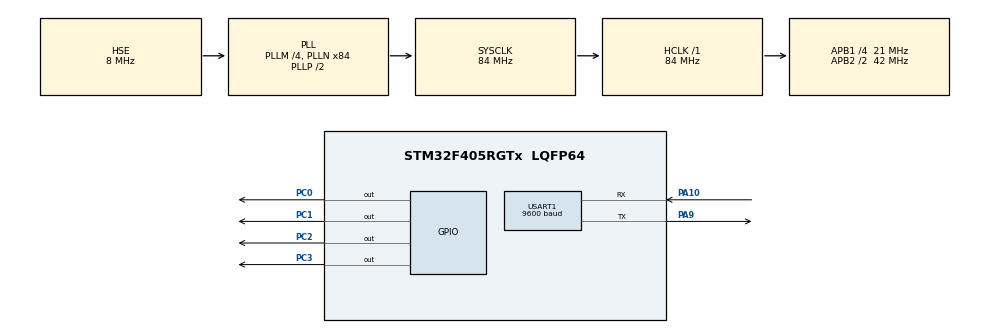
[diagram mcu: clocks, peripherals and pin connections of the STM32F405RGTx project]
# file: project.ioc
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Mcu.Family=STM32F4
Mcu.Name=STM32F405RGTx
Mcu.Package=LQFP64
NVIC.PriorityGroup=NVIC_PRIORITYGROUP_4
PA10.Mode=Asynchronous
PA10.Signal=USART1_RX
PA9.Mode=Asynchronous
PA9.Signal=USART1_TX
PC0.GPIO_ModeDefaultOutputPP=GPIO_MODE_OUTPUT_PP
PC0.GPIO_PuPd=GPIO_PULLUP
PC0.GPIO_Speed=GPIO_SPEED_FREQ_HIGH
PC0.PinState=GPIO_PIN_RESET
PC0.Signal=GPIO_Output
PC1.GPIO_PuPd=GPIO_PULLUP
PC1.GPIO_Speed=GPIO_SPEED_FREQ_HIGH
PC1.PinState=GPIO_PIN_RESET
PC1.Signal=GPIO_Output
PC2.GPIO_PuPd=GPIO_PULLUP
PC2.GPIO_Speed=GPIO_SPEED_FREQ_HIGH
PC2.Signal=GPIO_Output
PC3.GPIO_PuPd=GPIO_PULLUP
PC3.GPIO_Speed=GPIO_SPEED_FREQ_HIGH
PC3.Signal=GPIO_Output
PH0-OSC_IN.Mode=HSE-External-Oscillator
PH0-OSC_IN.Signal=RCC_OSC_IN
PH1-OSC_OUT.Mode=HSE-External-Oscillator
PH1-OSC_OUT.Signal=RCC_OSC_OUT
ProjectManager.HeapSize=0x200
ProjectManager.StackSize=0x400
ProjectManager.TargetToolchain=MDK-ARM V5
RCC.48MHZClocksFreq_Value=42000000
RCC.AHBFreq_Value=84000000
RCC.APB1CLKDivider=RCC_HCLK_DIV4
RCC.APB1Freq_Value=21000000
RCC.APB1TimFreq_Value=42000000
RCC.APB2CLKDivider=RCC_HCLK_DIV2
RCC.APB2Freq_Value=42000000
RCC.APB2TimFreq_Value=84000000
RCC.CortexFreq_Value=84000000
RCC.HCLKFreq_Value=84000000
RCC.HSE_VALUE=8000000
RCC.HSI_VALUE=16000000
RCC.LSE_VALUE=32768
RCC.PLLM=4
RCC.PLLN=84
RCC.PLLSourceVirtual=RCC_PLLSOURCE_HSE
RCC.SYSCLKFreq_VALUE=84000000
RCC.SYSCLKSource=RCC_SYSCLKSOURCE_PLLCLK
RCC.VCOOutputFreq_Value=168000000
USART1.BaudRate=9600
board=project

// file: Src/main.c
/**
  ******************************************************************************
  * File Name          : main.c
  * Description        : Main program body
  ******************************************************************************
  *
  * COPYRIGHT(c) 2018 STMicroelectronics
  *
  * Redistribution and use in source and binary forms, with or without modification,
  * are permitted provided that the following conditions are met:
  *   1. Redistributions of source code must retain the above copyright notice,
  *      this list of conditions and the following disclaimer.
  *   2. Redistributions in binary form must reproduce the above copyright notice,
  *      this list of conditions and the following disclaimer in the documentation
  *      and/or other materials provided with the distribution.
  *   3. Neither the name of STMicroelectronics nor the names of its contributors
  *      may be used to endorse or promote products derived from this software
  *      without specific prior written permission.
  *
  * THIS SOFTWARE IS PROVIDED BY THE COPYRIGHT HOLDERS AND CONTRIBUTORS "AS IS"
  * AND ANY EXPRESS OR IMPLIED WARRANTIES, INCLUDING, BUT NOT LIMITED TO, THE
  * IMPLIED WARRANTIES OF MERCHANTABILITY AND FITNESS FOR A PARTICULAR PURPOSE ARE
  * DISCLAIMED. IN NO EVENT SHALL THE COPYRIGHT HOLDER OR CONTRIBUTORS BE LIABLE
  * FOR ANY DIRECT, INDIRECT, INCIDENTAL, SPECIAL, EXEMPLARY, OR CONSEQUENTIAL
  * DAMAGES (INCLUDING, BUT NOT LIMITED TO, PROCUREMENT OF SUBSTITUTE GOODS OR
  * SERVICES; LOSS OF USE, DATA, OR PROFITS; OR BUSINESS INTERRUPTION) HOWEVER
  * CAUSED AND ON ANY THEORY OF LIABILITY, WHETHER IN CONTRACT, STRICT LIABILITY,
  * OR TORT (INCLUDING NEGLIGENCE OR OTHERWISE) ARISING IN ANY WAY OUT OF THE USE
  * OF THIS SOFTWARE, EVEN IF ADVISED OF THE POSSIBILITY OF SUCH DAMAGE.
  *
  ******************************************************************************
  */
#include "stm32f4xx_hal.h"
#include "usart.h"
#include "gpio.h"
#include "ads1115.h"
#include "ad8253.h"

/* USER CODE BEGIN PV */
/* Private variables ---------------------------------------------------------*/

/* USER CODE END PV */

void SystemClock_Config(void);
void Error_Handler(void);

/* USER CODE BEGIN PFP */
/* Private function prototypes -----------------------------------------------*/

/* USER CODE END PFP */

/* USER CODE BEGIN 0 */
int fputc(int ch, FILE *f)
{
    HAL_UART_Transmit(&huart1, (uint8_t*)&ch ,1, 0xffff);

    return ch;
}
/* USER CODE END 0 */

int main(void)
{

  /* USER CODE BEGIN 1 */
    double AD_value;
  /* USER CODE END 1 */

  /* MCU Configuration----------------------------------------------------------*/

  /* Reset of all peripherals, Initializes the Flash interface and the Systick. */
  HAL_Init();

  /* Configure the system clock */
  SystemClock_Config();

  /* Initialize all configured peripherals */
  MX_GPIO_Init();
  MX_USART1_UART_Init();

  /* Infinite loop */
  while (1)
  {
        AD_value = ADS1115_Getdata(1);
        AD_value =(AD_value* 24620)/65536;
        if(AD_value < 500)
            AD8253_Gain_1();
        else  if(AD_value > 500 && AD_value < 1000)
            AD8253_Gain_10();
        else  if(AD_value > 1000 && AD_value <1500)
            AD8253_Gain_100();
        else  if(AD_value > 1500 && AD_value <2000)
            AD8253_Gain_1();
        HAL_Delay(10);
  }

}

/** System Clock Configuration
*/
void SystemClock_Config(void)
{

  RCC_OscInitTypeDef RCC_OscInitStruct;
  RCC_ClkInitTypeDef RCC_ClkInitStruct;

  __HAL_RCC_PWR_CLK_ENABLE();

  __HAL_PWR_VOLTAGESCALING_CONFIG(PWR_REGULATOR_VOLTAGE_SCALE1);

  RCC_OscInitStruct.OscillatorType = RCC_OSCILLATORTYPE_HSE;
  RCC_OscInitStruct.HSEState = RCC_HSE_ON;
  RCC_OscInitStruct.PLL.PLLState = RCC_PLL_ON;
  RCC_OscInitStruct.PLL.PLLSource = RCC_PLLSOURCE_HSE;
  RCC_OscInitStruct.PLL.PLLM = 4;
  RCC_OscInitStruct.PLL.PLLN = 84;
  RCC_OscInitStruct.PLL.PLLP = RCC_PLLP_DIV2;
  RCC_OscInitStruct.PLL.PLLQ = 4;
  if (HAL_RCC_OscConfig(&RCC_OscInitStruct) != HAL_OK)
  {
    Error_Handler();
  }

  RCC_ClkInitStruct.ClockType = RCC_CLOCKTYPE_HCLK|RCC_CLOCKTYPE_SYSCLK
                              |RCC_CLOCKTYPE_PCLK1|RCC_CLOCKTYPE_PCLK2;
  RCC_ClkInitStruct.SYSCLKSource = RCC_SYSCLKSOURCE_PLLCLK;
  RCC_ClkInitStruct.AHBCLKDivider = RCC_SYSCLK_DIV1;
  RCC_ClkInitStruct.APB1CLKDivider = RCC_HCLK_DIV4;
  RCC_ClkInitStruct.APB2CLKDivider = RCC_HCLK_DIV2;
  if (HAL_RCC_ClockConfig(&RCC_ClkInitStruct, FLASH_LATENCY_2) != HAL_OK)
  {
    Error_Handler();
  }

  HAL_SYSTICK_Config(HAL_RCC_GetHCLKFreq()/1000);

  HAL_SYSTICK_CLKSourceConfig(SYSTICK_CLKSOURCE_HCLK);

  /* SysTick_IRQn interrupt configuration */
  HAL_NVIC_SetPriority(SysTick_IRQn, 0, 0);
}

void Error_Handler(void)
{
  while(1)
  {
  }
}

/************************ (C) COPYRIGHT STMicroelectronics *****END OF FILE****/
